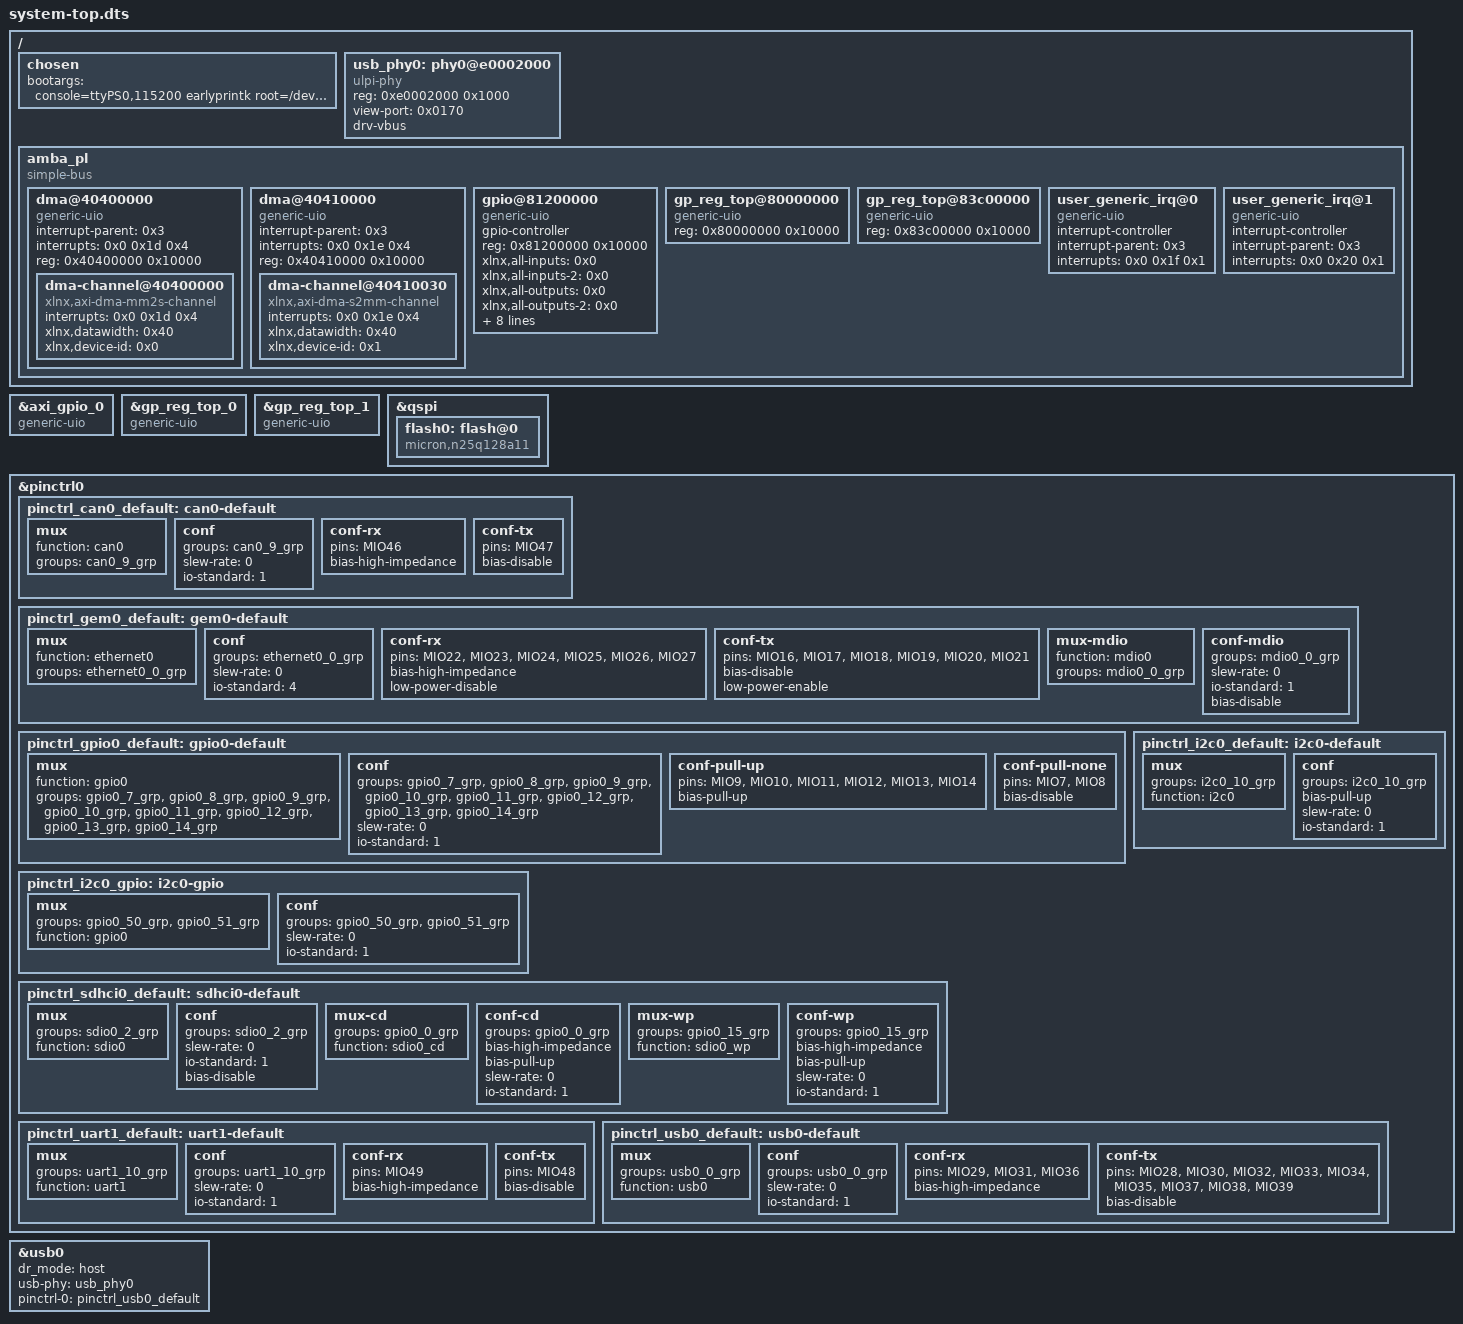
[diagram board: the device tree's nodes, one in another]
/dts-v1/;
/include/ "system-conf.dtsi"
/ {
    chosen {
		bootargs = "console=ttyPS0,115200 earlyprintk root=/dev/nfs nfsroot=192.168.15.10:/home/rootfs_ubuntu/rootfs,tcp nolock ip=192.168.15.11:192.168.15.10:192.168.15.1:255.255.255.0:jf315:eth0:off rw uio_pdrv_genirq.of_id=generic-uio";
	}; 
	usb_phy0: phy0@e0002000 {
		//compatible = "usb-nop-xceiv";
		compatible = "ulpi-phy";
		#phy-cells = <0>;
		reg = <0xe0002000 0x1000>;
		view-port = <0x0170>;
		drv-vbus;
	};

amba_pl {
		#address-cells = <0x1>;
		#size-cells = <0x1>;
		compatible = "simple-bus";
		ranges;

		dma@40400000 {
			#dma-cells = <0x1>;
			compatible = "generic-uio";
			interrupt-parent = <0x3>;
			interrupts = <0x0 0x1d 0x4>;
			reg = <0x40400000 0x10000>;

			dma-channel@40400000 {
				compatible = "xlnx,axi-dma-mm2s-channel";
				interrupts = <0x0 0x1d 0x4>;
				xlnx,datawidth = <0x40>;
				xlnx,device-id = <0x0>;
			};
		};

		dma@40410000 {
			#dma-cells = <0x1>;
			compatible = "generic-uio";
			interrupt-parent = <0x3>;
			interrupts = <0x0 0x1e 0x4>;
			reg = <0x40410000 0x10000>;

			dma-channel@40410030 {
				compatible = "xlnx,axi-dma-s2mm-channel";
				interrupts = <0x0 0x1e 0x4>;
				xlnx,datawidth = <0x40>;
				xlnx,device-id = <0x1>;
			};
		};

		gpio@81200000 {
			#gpio-cells = <0x2>;
			compatible = "generic-uio";
			gpio-controller;
			reg = <0x81200000 0x10000>;
			xlnx,all-inputs = <0x0>;
			xlnx,all-inputs-2 = <0x0>;
			xlnx,all-outputs = <0x0>;
			xlnx,all-outputs-2 = <0x0>;
			xlnx,dout-default = <0x0>;
			xlnx,dout-default-2 = <0x0>;
			xlnx,gpio-width = <0xc>;
			xlnx,gpio2-width = <0x20>;
			xlnx,interrupt-present = <0x0>;
			xlnx,is-dual = <0x0>;
			xlnx,tri-default = <0x0>;
			xlnx,tri-default-2 = <0xffffffff>;
		};

		gp_reg_top@80000000 {
			compatible = "generic-uio";
			reg = <0x80000000 0x10000>;
		};

		gp_reg_top@83c00000 {
			compatible = "generic-uio";
			reg = <0x83c00000 0x10000>;
		};

		user_generic_irq@0 {
			compatible = "generic-uio";
			status = "okay";
			interrupt-controller;
			interrupt-parent = <0x3>;
			interrupts = <0x0 0x1f 0x1>;
		};

		user_generic_irq@1 {
			compatible = "generic-uio";
			status = "okay";
			interrupt-controller;
			interrupt-parent = <0x3>;
			interrupts = <0x0 0x20 0x1>;
		};
	};
};

&axi_gpio_0 {
	compatible = "generic-uio";
};

&gp_reg_top_0 {
	compatible = "generic-uio";
};

&gp_reg_top_1 {
	compatible = "generic-uio";
};

&qspi {
	flash0: flash@0 {
		compatible = "s25fl256s1";
	};
};

&qspi {
	flash0: flash@0 {
		compatible = "micron,n25q128a11";
	};
};
&pinctrl0 {
	pinctrl_can0_default: can0-default {
		mux {
			function = "can0";
			groups = "can0_9_grp";
		};

		conf {
			groups = "can0_9_grp";
			slew-rate = <0>;
			io-standard = <1>;
		};

		conf-rx {
			pins = "MIO46";
			bias-high-impedance;
		};

		conf-tx {
			pins = "MIO47";
			bias-disable;
		};
	};

	pinctrl_gem0_default: gem0-default {
		mux {
			function = "ethernet0";
			groups = "ethernet0_0_grp";
		};

		conf {
			groups = "ethernet0_0_grp";
			slew-rate = <0>;
			io-standard = <4>;
		};

		conf-rx {
			pins = "MIO22", "MIO23", "MIO24", "MIO25", "MIO26", "MIO27";
			bias-high-impedance;
			low-power-disable;
		};

		conf-tx {
			pins = "MIO16", "MIO17", "MIO18", "MIO19", "MIO20", "MIO21";
			bias-disable;
			low-power-enable;
		};

		mux-mdio {
			function = "mdio0";
			groups = "mdio0_0_grp";
		};

		conf-mdio {
			groups = "mdio0_0_grp";
			slew-rate = <0>;
			io-standard = <1>;
			bias-disable;
		};
	};

	pinctrl_gpio0_default: gpio0-default {
		mux {
			function = "gpio0";
			groups = "gpio0_7_grp", "gpio0_8_grp", "gpio0_9_grp",
				 "gpio0_10_grp", "gpio0_11_grp", "gpio0_12_grp",
				 "gpio0_13_grp", "gpio0_14_grp";
		};

		conf {
			groups = "gpio0_7_grp", "gpio0_8_grp", "gpio0_9_grp",
				 "gpio0_10_grp", "gpio0_11_grp", "gpio0_12_grp",
				 "gpio0_13_grp", "gpio0_14_grp";
			slew-rate = <0>;
			io-standard = <1>;
		};

		conf-pull-up {
			pins = "MIO9", "MIO10", "MIO11", "MIO12", "MIO13", "MIO14";
			bias-pull-up;
		};

		conf-pull-none {
			pins = "MIO7", "MIO8";
			bias-disable;
		};
	};

	pinctrl_i2c0_default: i2c0-default {
		mux {
			groups = "i2c0_10_grp";
			function = "i2c0";
		};

		conf {
			groups = "i2c0_10_grp";
			bias-pull-up;
			slew-rate = <0>;
			io-standard = <1>;
		};
	};

	pinctrl_i2c0_gpio: i2c0-gpio {
		mux {
			groups = "gpio0_50_grp", "gpio0_51_grp";
			function = "gpio0";
		};

		conf {
			groups = "gpio0_50_grp", "gpio0_51_grp";
			slew-rate = <0>;
			io-standard = <1>;
		};
	};

	pinctrl_sdhci0_default: sdhci0-default {
		mux {
			groups = "sdio0_2_grp";
			function = "sdio0";
		};

		conf {
			groups = "sdio0_2_grp";
			slew-rate = <0>;
			io-standard = <1>;
			bias-disable;
		};

		mux-cd {
			groups = "gpio0_0_grp";
			function = "sdio0_cd";
		};

		conf-cd {
			groups = "gpio0_0_grp";
			bias-high-impedance;
			bias-pull-up;
			slew-rate = <0>;
			io-standard = <1>;
		};

		mux-wp {
			groups = "gpio0_15_grp";
			function = "sdio0_wp";
		};

		conf-wp {
			groups = "gpio0_15_grp";
			bias-high-impedance;
			bias-pull-up;
			slew-rate = <0>;
			io-standard = <1>;
		};
	};

	pinctrl_uart1_default: uart1-default {
		mux {
			groups = "uart1_10_grp";
			function = "uart1";
		};

		conf {
			groups = "uart1_10_grp";
			slew-rate = <0>;
			io-standard = <1>;
		};

		conf-rx {
			pins = "MIO49";
			bias-high-impedance;
		};

		conf-tx {
			pins = "MIO48";
			bias-disable;
		};
	};

	pinctrl_usb0_default: usb0-default {
		mux {
			groups = "usb0_0_grp";
			function = "usb0";
		};

		conf {
			groups = "usb0_0_grp";
			slew-rate = <0>;
			io-standard = <1>;
		};

		conf-rx {
			pins = "MIO29", "MIO31", "MIO36";
			bias-high-impedance;
		};

		conf-tx {
			pins = "MIO28", "MIO30", "MIO32", "MIO33", "MIO34",
			       "MIO35", "MIO37", "MIO38", "MIO39";
			bias-disable;
		};
	};
};
&usb0 {
	status = "okay";
	dr_mode = "host";
	usb-phy = <&usb_phy0>;
	pinctrl-names = "default";
	pinctrl-0 = <&pinctrl_usb0_default>;
};
